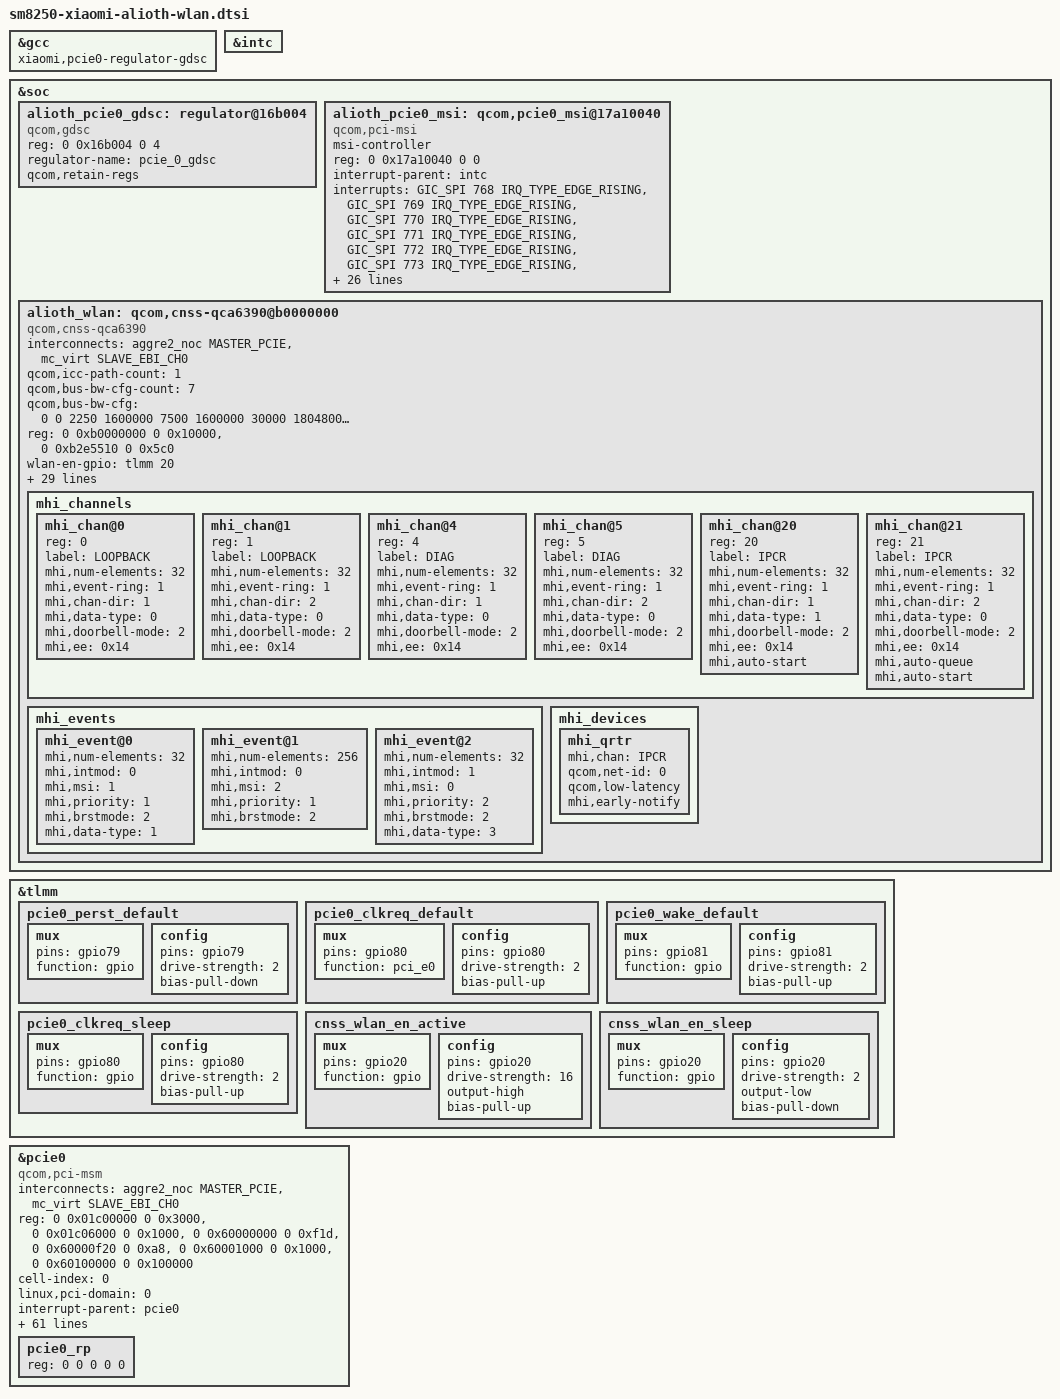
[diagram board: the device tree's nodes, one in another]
// SPDX-License-Identifier: GPL-2.0-only
/* Donor Kona/alioth QCA6390 connection; native clock IDs and ICC bindings. */
#include <dt-bindings/clock/qcom,gcc-sm8250.h>
#include <dt-bindings/interconnect/qcom,sm8250.h>

&gcc { xiaomi,pcie0-regulator-gdsc; };
&intc { #address-cells = <0>; };

&soc {
 alioth_pcie0_gdsc: regulator@16b004 {
  compatible = "qcom,gdsc";
  reg = <0 0x16b004 0 4>;
  regulator-name = "pcie_0_gdsc";
  qcom,retain-regs;
 };
alioth_pcie0_msi: qcom,pcie0_msi@17a10040 {
		compatible = "qcom,pci-msi";
		msi-controller;
		reg = <0 0x17a10040 0 0>;
		interrupt-parent = <&intc>;
		interrupts = <GIC_SPI 768 IRQ_TYPE_EDGE_RISING>,
			<GIC_SPI 769 IRQ_TYPE_EDGE_RISING>,
			<GIC_SPI 770 IRQ_TYPE_EDGE_RISING>,
			<GIC_SPI 771 IRQ_TYPE_EDGE_RISING>,
			<GIC_SPI 772 IRQ_TYPE_EDGE_RISING>,
			<GIC_SPI 773 IRQ_TYPE_EDGE_RISING>,
			<GIC_SPI 774 IRQ_TYPE_EDGE_RISING>,
			<GIC_SPI 775 IRQ_TYPE_EDGE_RISING>,
			<GIC_SPI 776 IRQ_TYPE_EDGE_RISING>,
			<GIC_SPI 777 IRQ_TYPE_EDGE_RISING>,
			<GIC_SPI 778 IRQ_TYPE_EDGE_RISING>,
			<GIC_SPI 779 IRQ_TYPE_EDGE_RISING>,
			<GIC_SPI 780 IRQ_TYPE_EDGE_RISING>,
			<GIC_SPI 781 IRQ_TYPE_EDGE_RISING>,
			<GIC_SPI 782 IRQ_TYPE_EDGE_RISING>,
			<GIC_SPI 783 IRQ_TYPE_EDGE_RISING>,
			<GIC_SPI 784 IRQ_TYPE_EDGE_RISING>,
			<GIC_SPI 785 IRQ_TYPE_EDGE_RISING>,
			<GIC_SPI 786 IRQ_TYPE_EDGE_RISING>,
			<GIC_SPI 787 IRQ_TYPE_EDGE_RISING>,
			<GIC_SPI 788 IRQ_TYPE_EDGE_RISING>,
			<GIC_SPI 789 IRQ_TYPE_EDGE_RISING>,
			<GIC_SPI 790 IRQ_TYPE_EDGE_RISING>,
			<GIC_SPI 791 IRQ_TYPE_EDGE_RISING>,
			<GIC_SPI 792 IRQ_TYPE_EDGE_RISING>,
			<GIC_SPI 793 IRQ_TYPE_EDGE_RISING>,
			<GIC_SPI 794 IRQ_TYPE_EDGE_RISING>,
			<GIC_SPI 795 IRQ_TYPE_EDGE_RISING>,
			<GIC_SPI 796 IRQ_TYPE_EDGE_RISING>,
			<GIC_SPI 797 IRQ_TYPE_EDGE_RISING>,
			<GIC_SPI 798 IRQ_TYPE_EDGE_RISING>,
			<GIC_SPI 799 IRQ_TYPE_EDGE_RISING>;
	};
alioth_wlan: qcom,cnss-qca6390@b0000000 {
		compatible = "qcom,cnss-qca6390";
		status = "okay";
		interconnects = <&aggre2_noc MASTER_PCIE &mc_virt SLAVE_EBI_CH0>;
		interconnect-names = "wlan-ddr";
		qcom,icc-path-count = <1>;
		qcom,bus-bw-cfg-count = <7>;
		qcom,bus-bw-cfg = <0 0 2250 1600000 7500 1600000
			30000 1804800 100000 1804800 175000 6220800 7500 2188800>;
		reg = <0 0xb0000000 0 0x10000>,
		      <0 0xb2e5510 0 0x5c0>;
		reg-names = "smmu_iova_ipa", "tcs_cmd";
		wlan-en-gpio = <&tlmm 20 0>;
		qcom,bt-en-gpio = <&tlmm 21 0>;
		qcom,sw-ctrl-gpio = <&tlmm 124 0>;
		pinctrl-names = "wlan_en_active", "wlan_en_sleep";
		pinctrl-0 = <&cnss_wlan_en_active>;
		pinctrl-1 = <&cnss_wlan_en_sleep>;
		qcom,wlan-rc-num = <0>;
		qcom,wlan-ramdump-dynamic = <0x420000>;
		qcom,smmu-s1-enable;
		qcom,converged-dt;
		cnss-daemon-support;
		qcom,cmd_db_name = "smpf2";
		use-nv-mac;
		qcom,set-wlaon-pwr-ctrl;
		cnss-enable-self-recovery;

		vdd-wlan-aon-supply = <&vreg_s6a_0p95>;
		qcom,vdd-wlan-aon-config = <950000 952000 0 0 1>;
		vdd-wlan-dig-supply = <&vreg_s6a_0p95>;
		qcom,vdd-wlan-dig-config = <950000 952000 0 0 1>;
		vdd-wlan-io-supply = <&vreg_s4a_1p8>;
		qcom,vdd-wlan-io-config = <1800000 1800000 0 0 1>;
		vdd-wlan-rfa1-supply = <&vreg_s5a_1p9>;
		qcom,vdd-wlan-rfa1-config = <1904000 1904000 0 0 1>;
		vdd-wlan-rfa2-supply = <&vreg_s8c_1p3>;
		qcom,vdd-wlan-rfa2-config = <1352000 1352000 0 0 1>;

		mhi,max-channels = <30>;
		mhi,timeout = <10000>;
		mhi,buffer-len = <0x8000>;
		mhi,m2-no-db-access;

		mhi_channels {
			#address-cells = <1>;
			#size-cells = <0>;

			mhi_chan@0 {
				reg = <0>;
				label = "LOOPBACK";
				mhi,num-elements = <32>;
				mhi,event-ring = <1>;
				mhi,chan-dir = <1>;
				mhi,data-type = <0>;
				mhi,doorbell-mode = <2>;
				mhi,ee = <0x14>;
			};

			mhi_chan@1 {
				reg = <1>;
				label = "LOOPBACK";
				mhi,num-elements = <32>;
				mhi,event-ring = <1>;
				mhi,chan-dir = <2>;
				mhi,data-type = <0>;
				mhi,doorbell-mode = <2>;
				mhi,ee = <0x14>;
			};

			mhi_chan@4 {
				reg = <4>;
				label = "DIAG";
				mhi,num-elements = <32>;
				mhi,event-ring = <1>;
				mhi,chan-dir = <1>;
				mhi,data-type = <0>;
				mhi,doorbell-mode = <2>;
				mhi,ee = <0x14>;
			};

			mhi_chan@5 {
				reg = <5>;
				label = "DIAG";
				mhi,num-elements = <32>;
				mhi,event-ring = <1>;
				mhi,chan-dir = <2>;
				mhi,data-type = <0>;
				mhi,doorbell-mode = <2>;
				mhi,ee = <0x14>;
			};

			mhi_chan@20 {
				reg = <20>;
				label = "IPCR";
				mhi,num-elements = <32>;
				mhi,event-ring = <1>;
				mhi,chan-dir = <1>;
				mhi,data-type = <1>;
				mhi,doorbell-mode = <2>;
				mhi,ee = <0x14>;
				mhi,auto-start;
			};

			mhi_chan@21 {
				reg = <21>;
				label = "IPCR";
				mhi,num-elements = <32>;
				mhi,event-ring = <1>;
				mhi,chan-dir = <2>;
				mhi,data-type = <0>;
				mhi,doorbell-mode = <2>;
				mhi,ee = <0x14>;
				mhi,auto-queue;
				mhi,auto-start;
			};
		};

		mhi_events {
			mhi_event@0 {
				mhi,num-elements = <32>;
				mhi,intmod = <0>;
				mhi,msi = <1>;
				mhi,priority = <1>;
				mhi,brstmode = <2>;
				mhi,data-type = <1>;
			};

			mhi_event@1 {
				mhi,num-elements = <256>;
				mhi,intmod = <0>;
				mhi,msi = <2>;
				mhi,priority = <1>;
				mhi,brstmode = <2>;
			};

			mhi_event@2 {
				mhi,num-elements = <32>;
				mhi,intmod = <1>;
				mhi,msi = <0>;
				mhi,priority = <2>;
				mhi,brstmode = <2>;
				mhi,data-type = <3>;
			};
		};

		mhi_devices {
			mhi_qrtr {
				mhi,chan = "IPCR";
				qcom,net-id = <0>;
				qcom,low-latency;
				mhi,early-notify;
			};
		};
	};
};

&tlmm {
pcie0_perst_default: pcie0_perst_default {
				mux {
					pins = "gpio79";
					function = "gpio";
				};

				config {
					pins = "gpio79";
					drive-strength = <2>;
					bias-pull-down;
				};
			};
pcie0_clkreq_default: pcie0_clkreq_default {
				mux {
					pins = "gpio80";
					function = "pci_e0";
				};

				config {
					pins = "gpio80";
					drive-strength = <2>;
					bias-pull-up;
				};
			};
pcie0_wake_default: pcie0_wake_default {
				mux {
					pins = "gpio81";
					function = "gpio";
				};

				config {
					pins = "gpio81";
					drive-strength = <2>;
					bias-pull-up;
				};
			};
pcie0_clkreq_sleep: pcie0_clkreq_sleep {
				mux {
					pins = "gpio80";
					function = "gpio";
				};

				config {
					pins = "gpio80";
					drive-strength = <2>;
					bias-pull-up;
				};
			};
cnss_wlan_en_active: cnss_wlan_en_active {
				mux {
					pins = "gpio20";
					function = "gpio";
				};

				config {
					pins = "gpio20";
					drive-strength = <16>;
					output-high;
					bias-pull-up;
				};
			};
cnss_wlan_en_sleep: cnss_wlan_en_sleep {
				mux {
					pins = "gpio20";
					function = "gpio";
				};

				config {
					pins = "gpio20";
					drive-strength = <2>;
					output-low;
					bias-pull-down;
				};
			};
};

&pcie0 {
		compatible = "qcom,pci-msm";
		status = "okay";
		/delete-property/ power-domains;
		/delete-property/ power-domain-names;
		/delete-property/ phys;
		/delete-property/ phy-names;
		interconnects = <&aggre2_noc MASTER_PCIE &mc_virt SLAVE_EBI_CH0>;
		interconnect-names = "icc_path";

		reg = <0 0x01c00000 0 0x3000>,
			<0 0x01c06000 0 0x1000>,
			<0 0x60000000 0 0xf1d>,
			<0 0x60000f20 0 0xa8>,
			<0 0x60001000 0 0x1000>,
			<0 0x60100000 0 0x100000>;
		reg-names = "parf", "phy", "dm_core", "elbi", "iatu", "conf";

		cell-index = <0>;
		linux,pci-domain = <0>;

		#address-cells = <3>;
		#size-cells = <2>;
		ranges = <0x01000000 0x0 0x60200000 0 0x60200000 0x0 0x100000>,
			<0x02000000 0x0 0x60300000 0 0x60300000 0x0 0x3d00000>;

		interrupt-parent = <&pcie0>;
		interrupts = <0 1 2 3 4>;
		interrupt-names = "int_global_int", "int_a", "int_b", "int_c",
				"int_d";
		#interrupt-cells = <1>;
		interrupt-map-mask = <0 0 0 0xffffffff>;
		interrupt-map = <0 0 0 0 &intc GIC_SPI 140 IRQ_TYPE_LEVEL_HIGH
				0 0 0 1 &intc GIC_SPI 149 IRQ_TYPE_LEVEL_HIGH
				0 0 0 2 &intc GIC_SPI 150 IRQ_TYPE_LEVEL_HIGH
				0 0 0 3 &intc GIC_SPI 151 IRQ_TYPE_LEVEL_HIGH
				0 0 0 4 &intc GIC_SPI 152 IRQ_TYPE_LEVEL_HIGH>;
		msi-parent = <&alioth_pcie0_msi>;

		perst-gpio = <&tlmm 79 0>;
		wake-gpio = <&tlmm 81 0>;
		pinctrl-names = "default", "sleep";
		pinctrl-0 = <&pcie0_clkreq_default
				&pcie0_perst_default
				&pcie0_wake_default>;
		pinctrl-1 = <&pcie0_clkreq_sleep
				&pcie0_perst_default
				&pcie0_wake_default>;

		gdsc-vdd-supply = <&alioth_pcie0_gdsc>;
		vreg-1p8-supply = <&vreg_l9a_1p2>;
		vreg-0p9-supply = <&vreg_l5a_0p875>;
		vreg-cx-supply = <&VDD_CX_LEVEL>;
		qcom,vreg-1p8-voltage-level = <1200000 1200000 16000>;
		qcom,vreg-0p9-voltage-level = <880000 880000 73500>;
		qcom,vreg-cx-voltage-level = <RPMH_REGULATOR_LEVEL_MAX
						RPMH_REGULATOR_LEVEL_NOM 0>;
		qcom,bw-scale = <RPMH_REGULATOR_LEVEL_LOW_SVS 19200000
				RPMH_REGULATOR_LEVEL_LOW_SVS 19200000
				RPMH_REGULATOR_LEVEL_NOM 100000000>;

		clocks = <&gcc GCC_PCIE_0_PIPE_CLK>,
			<&rpmhcc RPMH_CXO_CLK>,
			<&gcc GCC_PCIE_0_AUX_CLK>,
			<&gcc GCC_PCIE_0_CFG_AHB_CLK>,
			<&gcc GCC_PCIE_0_MSTR_AXI_CLK>,
			<&gcc GCC_PCIE_0_SLV_AXI_CLK>,
			<&gcc GCC_PCIE_WIFI_CLKREF_EN>,
			<&gcc GCC_PCIE_0_SLV_Q2A_AXI_CLK>,
			<&gcc GCC_AGGRE_NOC_PCIE_TBU_CLK>,
			<&gcc GCC_PCIE0_PHY_REFGEN_CLK>,
			<&gcc GCC_DDRSS_PCIE_SF_TBU_CLK>;
		clock-names = "pcie_0_pipe_clk", "pcie_0_ref_clk_src",
				"pcie_0_aux_clk", "pcie_0_cfg_ahb_clk",
				"pcie_0_mstr_axi_clk", "pcie_0_slv_axi_clk",
				"pcie_0_ldo", "pcie_0_slv_q2a_axi_clk",
				"pcie_tbu_clk", "pcie_phy_refgen_clk",
				"pcie_ddrss_sf_tbu_clk";
		max-clock-frequency-hz = <0>, <0>, <19200000>, <0>, <0>, <0>,
					<0>, <0>, <0>, <0>, <100000000>, <0>;

		resets = <&gcc GCC_PCIE_0_BCR>,
			<&gcc GCC_PCIE_0_PHY_BCR>;
		reset-names = "pcie_0_core_reset",
				"pcie_0_phy_reset";

		dma-coherent;
		qcom,smmu-sid-base = <0x1c00>;
		iommu-map = <0x0 &apps_smmu 0x1c00 0x1>,
			<0x100 &apps_smmu 0x1c01 0x1>;

		qcom,boot-option = <0x1>;
		qcom,drv-supported;
		qcom,drv-l1ss-timeout-us = <10000>; /* 10ms */
		qcom,use-19p2mhz-aux-clk;
		qcom,no-l0s-supported;
		qcom,l1-2-th-scale = <2>; /* 1us */
		qcom,l1-2-th-value = <70>;
		qcom,slv-addr-space-size = <0x4000000>;
		qcom,ep-latency = <10>;

		qcom,config-recovery;

		qcom,pcie-phy-ver = <1102>;
		qcom,phy-status-offset = <0x814>;
		qcom,phy-status-bit = <6>;
		qcom,phy-power-down-offset = <0x840>;
		qcom,phy-sequence = <0x0840 0x03 0x0
				0x0094 0x08 0x0
				0x0154 0x34 0x0
				0x016c 0x08 0x0
				0x0058 0x0f 0x0
				0x00a4 0x42 0x0
				0x0110 0x24 0x0
				0x011c 0x03 0x0
				0x0118 0xb4 0x0
				0x010c 0x02 0x0
				0x01bc 0x11 0x0
				0x00bc 0x82 0x0
				0x00d4 0x03 0x0
				0x00d0 0x55 0x0
				0x00cc 0x55 0x0
				0x00b0 0x1a 0x0
				0x00ac 0x0a 0x0
				0x00c4 0x68 0x0
				0x00e0 0x02 0x0
				0x00dc 0xaa 0x0
				0x00d8 0xab 0x0
				0x00b8 0x34 0x0
				0x00b4 0x14 0x0
				0x0158 0x01 0x0
				0x0074 0x06 0x0
				0x007c 0x16 0x0
				0x0084 0x36 0x0
				0x0078 0x06 0x0
				0x0080 0x16 0x0
				0x0088 0x36 0x0
				0x01b0 0x1e 0x0
				0x01ac 0xca 0x0
				0x01b8 0x18 0x0
				0x01b4 0xa2 0x0
				0x0050 0x07 0x0
				0x0010 0x01 0x0
				0x001c 0x31 0x0
				0x0020 0x01 0x0
				0x0024 0xde 0x0
				0x0028 0x07 0x0
				0x0030 0x4c 0x0
				0x0034 0x06 0x0
				0x029c 0x12 0x0
				0x0284 0x35 0x0
				0x023c 0x11 0x0
				0x051c 0x03 0x0
				0x0518 0x1c 0x0
				0x0524 0x1e 0x0
				0x04e8 0x00 0x0
				0x04ec 0x0e 0x0
				0x04f0 0x4a 0x0
				0x04f4 0x0f 0x0
				0x05b4 0x04 0x0
				0x0434 0x7f 0x0
				0x0444 0x70 0x0
				0x0510 0x17 0x0
				0x04d4 0x04 0x0
				0x04d8 0x07 0x0
				0x0598 0xd4 0x0
				0x059c 0x54 0x0
				0x05a0 0xdb 0x0
				0x05a4 0x3b 0x0
				0x05a8 0x31 0x0
				0x0584 0x24 0x0
				0x0588 0xe4 0x0
				0x058c 0xec 0x0
				0x0590 0x3b 0x0
				0x0594 0x36 0x0
				0x0570 0x3f 0x0
				0x0574 0x3f 0x0
				0x0578 0xff 0x0
				0x057c 0x7f 0x0
				0x0580 0x14 0x0
				0x04fc 0x00 0x0
				0x04f8 0xc0 0x0
				0x0460 0x30 0x0
				0x0464 0x00 0x0
				0x05bc 0x0c 0x0
				0x04dc 0x1b 0x0
				0x0408 0x0c 0x0
				0x0414 0x03 0x0
				0x05b8 0x30 0x0
				0x09a4 0x01 0x0
				0x0c90 0x00 0x0
				0x0c40 0x01 0x0
				0x0c48 0x01 0x0
				0x0c50 0x00 0x0
				0x0cb4 0x33 0x0
				0x0cbc 0x00 0x0
				0x0ce0 0x58 0x0
				0x0ca4 0x0f 0x0
				0x0048 0x90 0x0
				0x0c1c 0xc1 0x0
				0x0988 0x77 0x0
				0x0998 0x0b 0x0
				0x08dc 0x0d 0x0
				0x09ec 0x12 0x0
				0x0800 0x00 0x0
				0x0844 0x03 0x0>;

		/delete-node/ interrupt-controller;

		pcie0_rp: pcie0_rp {
			reg = <0 0 0 0 0>;
		};
	};
